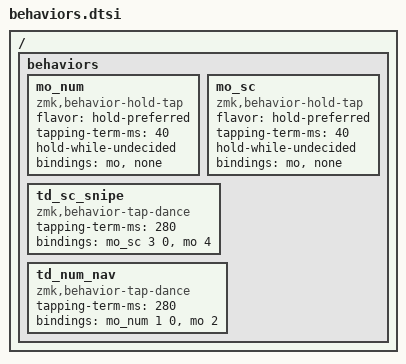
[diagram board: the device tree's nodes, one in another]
#include <dt-bindings/zmk/keys.h>
#include <dt-bindings/zmk/pointing.h>
#include <dt-bindings/zmk/modifiers.h>

/ {
    behaviors {













        // Left-hand HRM

        // Right-hand HRM












        // Right-thumb dance: hold = NUM layer; double-tap-and-hold = NAV
        // while held. Inner hold-tap is hold-preferred with a very short term
        // so a hold fires before the tap-dance counter can advance; a plain
        // single tap does nothing (&none).
        mo_num: mo_num {
            compatible = "zmk,behavior-hold-tap";
            #binding-cells = <2>;
            flavor       = "hold-preferred";
            tapping-term-ms = <40>;
            hold-while-undecided;
            bindings = <&mo>, <&none>;
        };

        // Left-thumb dance: hold = SCROLL layer; double-tap-and-hold = SNIPE.
        // Same shape as td_num_nav: hold-preferred inner with a short term so
        // the hold fires while the dance is still counting.
        mo_sc: mo_sc {
            compatible = "zmk,behavior-hold-tap";
            #binding-cells = <2>;
            flavor       = "hold-preferred";
            tapping-term-ms = <40>;
            hold-while-undecided;
            bindings = <&mo>, <&none>;
        };

        td_sc_snipe: td_sc_snipe {
            compatible = "zmk,behavior-tap-dance";
            #binding-cells = <0>;
            // window measured press-to-press (see td_num_nav note)
            tapping-term-ms = <280>;
            // 1) tap+hold (or just hold) = SCROLL
            // 2) double-tap, keep holding = SNIPE as a momentary layer
            bindings = <&mo_sc 3 0>, <&mo 4>;
        };

        td_num_nav: td_num_nav {
            compatible = "zmk,behavior-tap-dance";
            #binding-cells = <0>;
            // window measured press-to-press; a relaxed double-tap runs
            // 150-250ms so 170ms resolved to the single-tap binding (NUM)
            // before the second press registered
            tapping-term-ms = <280>;
            // 1) tap+hold (or just hold) = NUM
            // 2) double-tap, keep holding = NAV as a momentary layer
            bindings = <&mo_num 1 0>, <&mo 2>;
        };



    };
};
